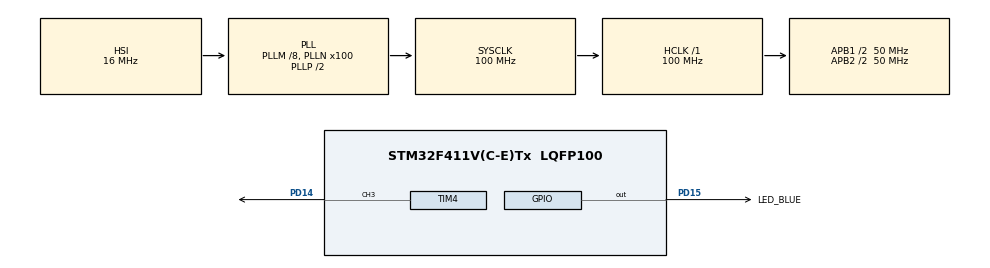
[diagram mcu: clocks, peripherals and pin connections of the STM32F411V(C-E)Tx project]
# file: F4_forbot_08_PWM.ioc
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Mcu.Family=STM32F4
Mcu.Name=STM32F411V(C-E)Tx
Mcu.Package=LQFP100
NVIC.PriorityGroup=NVIC_PRIORITYGROUP_4
PD14.Signal=S_TIM4_CH3
PD15.GPIO_Label=LED_BLUE
PD15.Signal=GPIO_Output
ProjectManager.HeapSize=0x200
ProjectManager.StackSize=0x400
ProjectManager.TargetToolchain=SW4STM32
RCC.48MHZClocksFreq_Value=50000000
RCC.AHBFreq_Value=100000000
RCC.APB1CLKDivider=RCC_HCLK_DIV2
RCC.APB1Freq_Value=50000000
RCC.APB1TimFreq_Value=100000000
RCC.APB2CLKDivider=RCC_HCLK_DIV2
RCC.APB2Freq_Value=50000000
RCC.APB2TimFreq_Value=100000000
RCC.CortexFreq_Value=100000000
RCC.HCLKFreq_Value=100000000
RCC.HSE_VALUE=8000000
RCC.HSI_VALUE=16000000
RCC.LSE_VALUE=32768
RCC.PLLM=8
RCC.PLLN=100
RCC.SYSCLKFreq_VALUE=100000000
RCC.SYSCLKSource=RCC_SYSCLKSOURCE_PLLCLK
RCC.VCOOutputFreq_Value=200000000
SH.S_TIM4_CH3.0=TIM4_CH3,PWM Generation3 CH3
TIM4.Channel-PWM\ Generation3\ CH3=TIM_CHANNEL_3
TIM4.OC3Preload_PWM=ENABLE
TIM4.Period=99
TIM4.Prescaler=4999
VP_TIM4_VS_ClockSourceINT.Mode=Internal
board=custom

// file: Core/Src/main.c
/* USER CODE BEGIN Header */
/**
  ******************************************************************************
  * @file           : main.c
  * @brief          : Main program body
  ******************************************************************************
  * @attention
  *
  * <h2><center>&copy; Copyright (c) 2021 STMicroelectronics.
  * All rights reserved.</center></h2>
  *
  * This software component is licensed by ST under BSD 3-Clause license,
  * the "License"; You may not use this file except in compliance with the
  * License. You may obtain a copy of the License at:
  *                        opensource.org/licenses/BSD-3-Clause
  *
  ******************************************************************************
  */
/* USER CODE END Header */
#include "main.h"

TIM_HandleTypeDef htim4;

void SystemClock_Config(void);
static void MX_GPIO_Init(void);
static void MX_TIM4_Init(void);
/* USER CODE BEGIN PFP */

//Przerwanie wywowy ³ywane z czestotliwoscia 1kHz

void przerwanie(void){

	static uint8_t InterruptPrescaler = 0; 	// licznik przerwan
	static uint8_t CzyRosnie = 1; 			// flaga kierunku zliczania
	static uint16_t Duty = 0;

	++InterruptPrescaler;					// Interpretacja numeru przerwania

	//Jezeli wywow³alo siê 40 przerwan z rzedu
	if( InterruptPrescaler == 40 ){

		InterruptPrescaler = 0;

		if ( Duty == 100 ){					// Jezeli wypelnienie jest rowne 100
			CzyRosnie = 0;					// Zmien kierunek zliczania w dol
			HAL_GPIO_TogglePin(LED_BLUE_GPIO_Port, LED_BLUE_Pin);
		}
		else if ( Duty == 0 ){				// Jezeli wypelnienie rowne 0
			CzyRosnie = 1;					// Zmien kierunek zliczania w gore

		}
		if ( CzyRosnie )					// Jezeli zliczamy w gore
			++Duty;							// Inkrementuj wartosci wypelnienia
		else 								// Jezeli zliczamy w dol
			--Duty;							// Dekrementuj wartosc wypelnienia

	}
	TIM4->CCR3 = Duty;						// Wstawienie wyliczonej wartosci wypelnienia do
											// rejestru timera odpowiedzialnego za wypelnienie generowanego sygnalu PWM

}

/* USER CODE END PFP */

int main(void)
{

  /* MCU Configuration--------------------------------------------------------*/

  /* Reset of all peripherals, Initializes the Flash interface and the Systick. */
  HAL_Init();

  /* Configure the system clock */
  SystemClock_Config();

  /* Initialize all configured peripherals */
  MX_GPIO_Init();
  MX_TIM4_Init();
  /* USER CODE BEGIN 2 */
  HAL_TIM_PWM_Start(&htim4, TIM_CHANNEL_3);

  /* USER CODE END 2 */

  /* Infinite loop */
  while (1)
  {

    /* USER CODE BEGIN 3 */

	  //HAL_Delay(1000);

  }
  /* USER CODE END 3 */
}

void SystemClock_Config(void)
{
  RCC_OscInitTypeDef RCC_OscInitStruct = {0};
  RCC_ClkInitTypeDef RCC_ClkInitStruct = {0};

  /** Configure the main internal regulator output voltage
  */
  __HAL_RCC_PWR_CLK_ENABLE();
  __HAL_PWR_VOLTAGESCALING_CONFIG(PWR_REGULATOR_VOLTAGE_SCALE1);
  /** Initializes the RCC Oscillators according to the specified parameters
  * in the RCC_OscInitTypeDef structure.
  */
  RCC_OscInitStruct.OscillatorType = RCC_OSCILLATORTYPE_HSI;
  RCC_OscInitStruct.HSIState = RCC_HSI_ON;
  RCC_OscInitStruct.HSICalibrationValue = RCC_HSICALIBRATION_DEFAULT;
  RCC_OscInitStruct.PLL.PLLState = RCC_PLL_ON;
  RCC_OscInitStruct.PLL.PLLSource = RCC_PLLSOURCE_HSI;
  RCC_OscInitStruct.PLL.PLLM = 8;
  RCC_OscInitStruct.PLL.PLLN = 100;
  RCC_OscInitStruct.PLL.PLLP = RCC_PLLP_DIV2;
  RCC_OscInitStruct.PLL.PLLQ = 4;
  if (HAL_RCC_OscConfig(&RCC_OscInitStruct) != HAL_OK)
  {
    Error_Handler();
  }
  /** Initializes the CPU, AHB and APB buses clocks
  */
  RCC_ClkInitStruct.ClockType = RCC_CLOCKTYPE_HCLK|RCC_CLOCKTYPE_SYSCLK
                              |RCC_CLOCKTYPE_PCLK1|RCC_CLOCKTYPE_PCLK2;
  RCC_ClkInitStruct.SYSCLKSource = RCC_SYSCLKSOURCE_PLLCLK;
  RCC_ClkInitStruct.AHBCLKDivider = RCC_SYSCLK_DIV1;
  RCC_ClkInitStruct.APB1CLKDivider = RCC_HCLK_DIV2;
  RCC_ClkInitStruct.APB2CLKDivider = RCC_HCLK_DIV2;

  if (HAL_RCC_ClockConfig(&RCC_ClkInitStruct, FLASH_LATENCY_3) != HAL_OK)
  {
    Error_Handler();
  }
}

static void MX_TIM4_Init(void)
{

  TIM_ClockConfigTypeDef sClockSourceConfig = {0};
  TIM_MasterConfigTypeDef sMasterConfig = {0};
  TIM_OC_InitTypeDef sConfigOC = {0};

  htim4.Instance = TIM4;
  htim4.Init.Prescaler = 4999;
  htim4.Init.CounterMode = TIM_COUNTERMODE_UP;
  htim4.Init.Period = 99;
  htim4.Init.ClockDivision = TIM_CLOCKDIVISION_DIV1;
  htim4.Init.AutoReloadPreload = TIM_AUTORELOAD_PRELOAD_DISABLE;
  if (HAL_TIM_Base_Init(&htim4) != HAL_OK)
  {
    Error_Handler();
  }
  sClockSourceConfig.ClockSource = TIM_CLOCKSOURCE_INTERNAL;
  if (HAL_TIM_ConfigClockSource(&htim4, &sClockSourceConfig) != HAL_OK)
  {
    Error_Handler();
  }
  if (HAL_TIM_PWM_Init(&htim4) != HAL_OK)
  {
    Error_Handler();
  }
  sMasterConfig.MasterOutputTrigger = TIM_TRGO_RESET;
  sMasterConfig.MasterSlaveMode = TIM_MASTERSLAVEMODE_DISABLE;
  if (HAL_TIMEx_MasterConfigSynchronization(&htim4, &sMasterConfig) != HAL_OK)
  {
    Error_Handler();
  }
  sConfigOC.OCMode = TIM_OCMODE_PWM1;
  sConfigOC.Pulse = 0;
  sConfigOC.OCPolarity = TIM_OCPOLARITY_HIGH;
  sConfigOC.OCFastMode = TIM_OCFAST_DISABLE;
  if (HAL_TIM_PWM_ConfigChannel(&htim4, &sConfigOC, TIM_CHANNEL_3) != HAL_OK)
  {
    Error_Handler();
  }
  HAL_TIM_MspPostInit(&htim4);

}

static void MX_GPIO_Init(void)
{
  GPIO_InitTypeDef GPIO_InitStruct = {0};

  /* GPIO Ports Clock Enable */
  __HAL_RCC_GPIOD_CLK_ENABLE();

  /*Configure GPIO pin Output Level */
  HAL_GPIO_WritePin(LED_BLUE_GPIO_Port, LED_BLUE_Pin, GPIO_PIN_RESET);

  /*Configure GPIO pin : LED_BLUE_Pin */
  GPIO_InitStruct.Pin = LED_BLUE_Pin;
  GPIO_InitStruct.Mode = GPIO_MODE_OUTPUT_PP;
  GPIO_InitStruct.Pull = GPIO_NOPULL;
  GPIO_InitStruct.Speed = GPIO_SPEED_FREQ_LOW;
  HAL_GPIO_Init(LED_BLUE_GPIO_Port, &GPIO_InitStruct);

}

void Error_Handler(void)
{
  __disable_irq();
  while (1)
  {
  }
}

/************************ (C) COPYRIGHT STMicroelectronics *****END OF FILE****/
